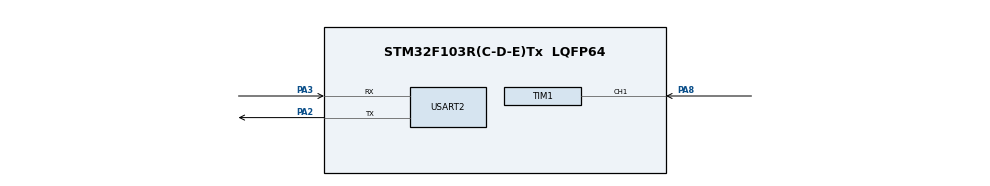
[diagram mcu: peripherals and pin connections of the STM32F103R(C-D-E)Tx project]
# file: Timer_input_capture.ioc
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Mcu.Family=STM32F1
Mcu.Name=STM32F103R(C-D-E)Tx
Mcu.Package=LQFP64
NVIC.PriorityGroup=NVIC_PRIORITYGROUP_4
NVIC.TIM1_CC_IRQn=true\:0\:0\:false\:false\:true\:true\:true
PA13.Mode=JTAG_5_pins
PA13.Signal=SYS_JTMS-SWDIO
PA14.Mode=JTAG_5_pins
PA14.Signal=SYS_JTCK-SWCLK
PA15.Mode=JTAG_5_pins
PA15.Signal=SYS_JTDI
PA2.Mode=Asynchronous
PA2.Signal=USART2_TX
PA3.Mode=Asynchronous
PA3.Signal=USART2_RX
PA8.Signal=S_TIM1_CH1
PB3.Mode=JTAG_5_pins
PB3.Signal=SYS_JTDO-TRACESWO
PB4.Mode=JTAG_5_pins
PB4.Signal=SYS_NJTRST
PD0-OSC_IN.Mode=HSE-External-Oscillator
PD0-OSC_IN.Signal=RCC_OSC_IN
PD1-OSC_OUT.Mode=HSE-External-Oscillator
PD1-OSC_OUT.Signal=RCC_OSC_OUT
ProjectManager.HeapSize=0x200
ProjectManager.StackSize=0x400
ProjectManager.TargetToolchain=MDK-ARM V5.27
RCC.AHBFreq_Value=64000000
RCC.APB1CLKDivider=RCC_HCLK_DIV2
RCC.APB1Freq_Value=32000000
RCC.APB1TimFreq_Value=64000000
RCC.APB2Freq_Value=64000000
RCC.APB2TimFreq_Value=64000000
RCC.HCLKFreq_Value=64000000
RCC.PLLMUL=RCC_PLL_MUL16
RCC.SYSCLKFreq_VALUE=64000000
RCC.SYSCLKSource=RCC_SYSCLKSOURCE_PLLCLK
RCC.USBFreq_Value=64000000
SH.S_TIM1_CH1.0=TIM1_CH1,Input_Capture1_from_TI1
TIM1.Channel-Input_Capture1_from_TI1=TIM_CHANNEL_1
TIM1.Period=65535
TIM1.Prescaler=0
USART2.VirtualMode=VM_ASYNC
board=custom

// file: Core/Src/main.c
/* USER CODE BEGIN Header */
/**
  ******************************************************************************
  * @file           : main.c
  * @brief          : Main program body
  ******************************************************************************
  * @attention
  *
  * <h2><center>&copy; Copyright (c) 2021 STMicroelectronics.
  * All rights reserved.</center></h2>
  *
  * This software component is licensed by ST under BSD 3-Clause license,
  * the "License"; You may not use this file except in compliance with the
  * License. You may obtain a copy of the License at:
  *                        opensource.org/licenses/BSD-3-Clause
  *
  ******************************************************************************
  */
/* USER CODE END Header */
#include "main.h"

/* USER CODE BEGIN Includes */
#include "stdio.h"
/* USER CODE END Includes */

/* USER CODE BEGIN PV */
	volatile uint32_t Frequency = 0;			//varibale for storing Frequency
	char str[30];								//string varibale for representing the message
	uint8_t i = 0;								//index
/* USER CODE END PV */

void SystemClock_Config(void);
static void MX_GPIO_Init(void);
static void MX_TIM1_Init(void);
static void MX_USART2_UART_Init(void);

int main(void)
{

  /* MCU Configuration--------------------------------------------------------*/

  /* Reset of all peripherals, Initializes the Flash interface and the Systick. */

  LL_APB2_GRP1_EnableClock(LL_APB2_GRP1_PERIPH_AFIO);
  LL_APB1_GRP1_EnableClock(LL_APB1_GRP1_PERIPH_PWR);

  NVIC_SetPriorityGrouping(NVIC_PRIORITYGROUP_4);

  /* System interrupt init*/

  /** ENABLE: Full SWJ (JTAG-DP + SW-DP): Reset State
  */
  LL_GPIO_AF_EnableRemap_SWJ();

  /* Configure the system clock */
  SystemClock_Config();

  /* Initialize all configured peripherals */
  MX_GPIO_Init();
  MX_TIM1_Init();
  MX_USART2_UART_Init();
  /* USER CODE BEGIN 2 */

	/* Configuring Timer1 */
	LL_TIM_EnableIT_CC1(TIM1);
	LL_TIM_CC_EnableChannel(TIM1, LL_TIM_CHANNEL_CH1);
	LL_TIM_EnableCounter(TIM1);
  /* USER CODE END 2 */

  /* Infinite loop */
  while (1)
  {

    /* USER CODE BEGIN 3 */

		/* print out the calculated frequency */
		int len = sprintf(str, "Frequency is: %dHz\n\r", Frequency);
		for (i; i<len; i++)
		{
		 LL_USART_TransmitData8(USART1, str[i]);
		 while(!LL_USART_IsActiveFlag_TXE(USART1));
		}
		i = 0;
  }
  /* USER CODE END 3 */
}

void SystemClock_Config(void)
{
  LL_FLASH_SetLatency(LL_FLASH_LATENCY_2);
  while(LL_FLASH_GetLatency()!= LL_FLASH_LATENCY_2)
  {
  }
  LL_RCC_HSI_SetCalibTrimming(16);
  LL_RCC_HSI_Enable();

   /* Wait till HSI is ready */
  while(LL_RCC_HSI_IsReady() != 1)
  {

  }
  LL_RCC_PLL_ConfigDomain_SYS(LL_RCC_PLLSOURCE_HSI_DIV_2, LL_RCC_PLL_MUL_16);
  LL_RCC_PLL_Enable();

   /* Wait till PLL is ready */
  while(LL_RCC_PLL_IsReady() != 1)
  {

  }
  LL_RCC_SetAHBPrescaler(LL_RCC_SYSCLK_DIV_1);
  LL_RCC_SetAPB1Prescaler(LL_RCC_APB1_DIV_2);
  LL_RCC_SetAPB2Prescaler(LL_RCC_APB2_DIV_1);
  LL_RCC_SetSysClkSource(LL_RCC_SYS_CLKSOURCE_PLL);

   /* Wait till System clock is ready */
  while(LL_RCC_GetSysClkSource() != LL_RCC_SYS_CLKSOURCE_STATUS_PLL)
  {

  }
  LL_Init1msTick(64000000);
  LL_SetSystemCoreClock(64000000);
}

static void MX_TIM1_Init(void)
{

  LL_TIM_InitTypeDef TIM_InitStruct = {0};

  LL_GPIO_InitTypeDef GPIO_InitStruct = {0};

  /* Peripheral clock enable */
  LL_APB2_GRP1_EnableClock(LL_APB2_GRP1_PERIPH_TIM1);

  LL_APB2_GRP1_EnableClock(LL_APB2_GRP1_PERIPH_GPIOA);
  /**TIM1 GPIO Configuration
  PA8   ------> TIM1_CH1
  */
  GPIO_InitStruct.Pin = LL_GPIO_PIN_8;
  GPIO_InitStruct.Mode = LL_GPIO_MODE_FLOATING;
  LL_GPIO_Init(GPIOA, &GPIO_InitStruct);

  /* TIM1 interrupt Init */
  NVIC_SetPriority(TIM1_CC_IRQn, NVIC_EncodePriority(NVIC_GetPriorityGrouping(),0, 0));
  NVIC_EnableIRQ(TIM1_CC_IRQn);

  TIM_InitStruct.Prescaler = 0;
  TIM_InitStruct.CounterMode = LL_TIM_COUNTERMODE_UP;
  TIM_InitStruct.Autoreload = 65535;
  TIM_InitStruct.ClockDivision = LL_TIM_CLOCKDIVISION_DIV1;
  TIM_InitStruct.RepetitionCounter = 0;
  LL_TIM_Init(TIM1, &TIM_InitStruct);
  LL_TIM_DisableARRPreload(TIM1);
  LL_TIM_SetTriggerOutput(TIM1, LL_TIM_TRGO_RESET);
  LL_TIM_DisableMasterSlaveMode(TIM1);
  LL_TIM_IC_SetActiveInput(TIM1, LL_TIM_CHANNEL_CH1, LL_TIM_ACTIVEINPUT_DIRECTTI);
  LL_TIM_IC_SetPrescaler(TIM1, LL_TIM_CHANNEL_CH1, LL_TIM_ICPSC_DIV1);
  LL_TIM_IC_SetFilter(TIM1, LL_TIM_CHANNEL_CH1, LL_TIM_IC_FILTER_FDIV1);
  LL_TIM_IC_SetPolarity(TIM1, LL_TIM_CHANNEL_CH1, LL_TIM_IC_POLARITY_RISING);

}

static void MX_USART2_UART_Init(void)
{

  LL_USART_InitTypeDef USART_InitStruct = {0};

  LL_GPIO_InitTypeDef GPIO_InitStruct = {0};

  /* Peripheral clock enable */
  LL_APB1_GRP1_EnableClock(LL_APB1_GRP1_PERIPH_USART2);

  LL_APB2_GRP1_EnableClock(LL_APB2_GRP1_PERIPH_GPIOA);
  /**USART2 GPIO Configuration
  PA2   ------> USART2_TX
  PA3   ------> USART2_RX
  */
  GPIO_InitStruct.Pin = LL_GPIO_PIN_2;
  GPIO_InitStruct.Mode = LL_GPIO_MODE_ALTERNATE;
  GPIO_InitStruct.Speed = LL_GPIO_SPEED_FREQ_HIGH;
  GPIO_InitStruct.OutputType = LL_GPIO_OUTPUT_PUSHPULL;
  LL_GPIO_Init(GPIOA, &GPIO_InitStruct);

  GPIO_InitStruct.Pin = LL_GPIO_PIN_3;
  GPIO_InitStruct.Mode = LL_GPIO_MODE_FLOATING;
  LL_GPIO_Init(GPIOA, &GPIO_InitStruct);

  USART_InitStruct.BaudRate = 115200;
  USART_InitStruct.DataWidth = LL_USART_DATAWIDTH_8B;
  USART_InitStruct.StopBits = LL_USART_STOPBITS_1;
  USART_InitStruct.Parity = LL_USART_PARITY_NONE;
  USART_InitStruct.TransferDirection = LL_USART_DIRECTION_TX_RX;
  USART_InitStruct.HardwareFlowControl = LL_USART_HWCONTROL_NONE;
  USART_InitStruct.OverSampling = LL_USART_OVERSAMPLING_16;
  LL_USART_Init(USART2, &USART_InitStruct);
  LL_USART_ConfigAsyncMode(USART2);
  LL_USART_Enable(USART2);

}

static void MX_GPIO_Init(void)
{

  /* GPIO Ports Clock Enable */
  LL_APB2_GRP1_EnableClock(LL_APB2_GRP1_PERIPH_GPIOD);
  LL_APB2_GRP1_EnableClock(LL_APB2_GRP1_PERIPH_GPIOA);
  LL_APB2_GRP1_EnableClock(LL_APB2_GRP1_PERIPH_GPIOB);

}

void Error_Handler(void)
{
}

/************************ (C) COPYRIGHT STMicroelectronics *****END OF FILE****/
